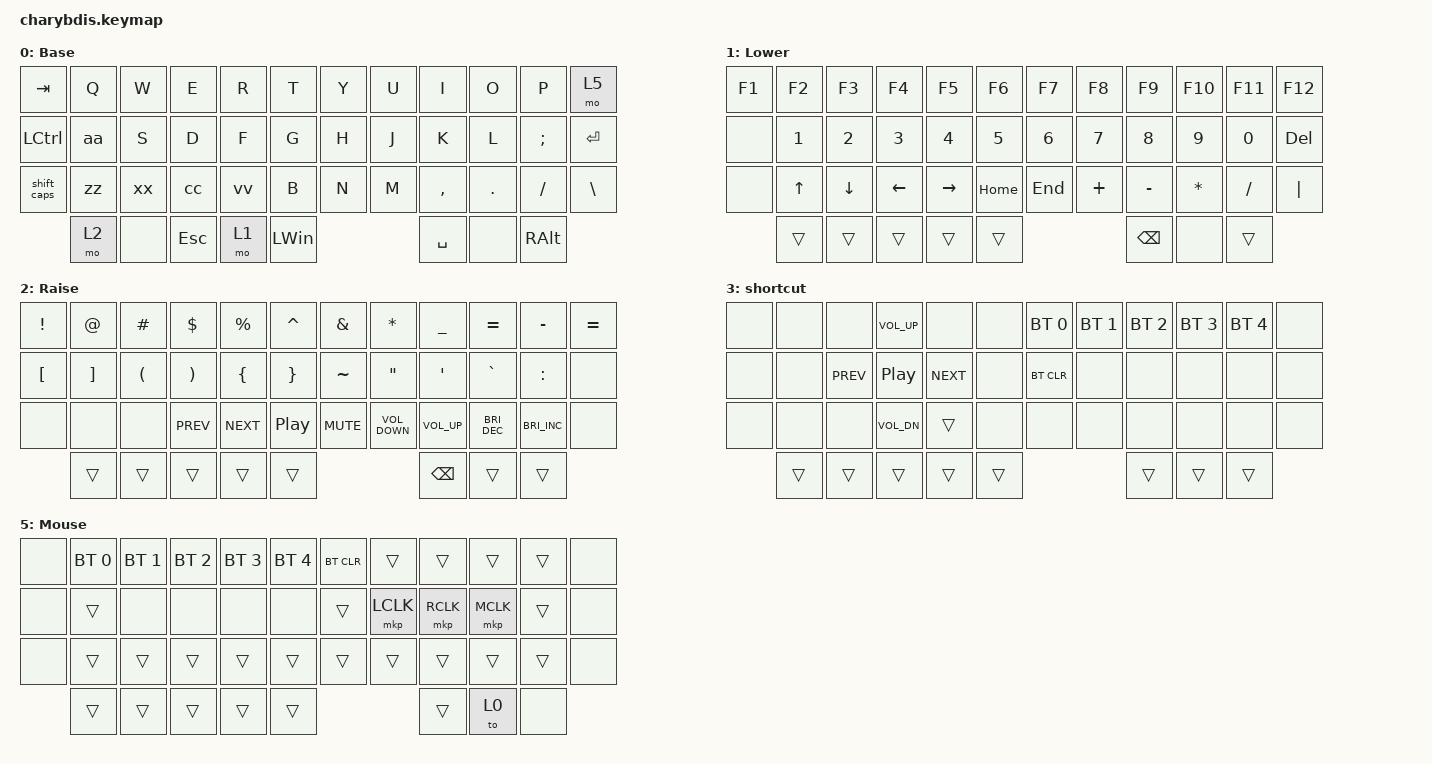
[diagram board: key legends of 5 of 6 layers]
#include <behaviors.dtsi>
#include <dt-bindings/zmk/bt.h>
#include <dt-bindings/zmk/keys.h>
#include <dt-bindings/zmk/mouse.h>

&lt {
    tapping-term-ms = <240>;
    flavor = "balanced";
    quick-tap-ms = <150>;
};

&mt {
    global-quick-tap;
    flavor = "tap-preferred";
    tapping-term-ms = <200>;
};

&sk {
    release-after-ms = <2000>;
    quick-release;
};

/ {
    combos {
        compatible = "zmk,combos";

        combo_esc {
            timeout-ms = <50>;
            key-positions = <0 1>;
            bindings = <&kp ESC>;
        };

        left_bkt {
            bindings = <&kp LEFT_BRACKET>;
            key-positions = <4 5>;
            timeout-ms = <50>;
        };

        right_bkt {
            bindings = <&kp RIGHT_BRACKET>;
            key-positions = <6 7>;
            timeout-ms = <50>;
        };

        left_par {
            bindings = <&kp LEFT_PARENTHESIS>;
            key-positions = <16 17>;
            timeout-ms = <50>;
        };

        right_par {
            bindings = <&kp RIGHT_PARENTHESIS>;
            key-positions = <18 19>;
            timeout-ms = <50>;
        };

        bac {
            bindings = <&kp BACKSLASH>;
            key-positions = <5 6>;
            timeout-ms = <50>;
        };

        pipe {
            bindings = <&kp PIPE>;
            key-positions = <17 18>;
            timeout-ms = <50>;
        };
    };

    behaviors {
        hm: homerow_mods {
            compatible = "zmk,behavior-hold-tap";
            label = "HOMEROW_MODS";
            bindings = <&kp>, <&kp>;

            #binding-cells = <2>;
            tapping-term-ms = <200>;
            quick-tap-ms = <180>;
            flavor = "tap-preferred";
        };

        ltq: ltq {
            compatible = "zmk,behavior-hold-tap";
            label = "LTQ";
            bindings = <&mo>, <&kp>;

            #binding-cells = <2>;
            tapping-term-ms = <200>;
            quick-tap-ms = <180>;
        };

        as: auto_shift {
            compatible = "zmk,behavior-hold-tap";
            label = "AUTO_SHIFT";
            bindings = <&kp>, <&kp>;

            #binding-cells = <2>;
            tapping-term-ms = <135>;
            quick-tap-ms = <0>;
        };

        shift_caps: shift_caps {
            compatible = "zmk,behavior-tap-dance";
            label = "shift_caps";
            #binding-cells = <0>;
            tapping-term-ms = <200>;
            bindings = <&kp LEFT_SHIFT>, <&caps_word>;
        };

        zz: zz {
            compatible = "zmk,behavior-tap-dance";
            label = "ZZ";
            #binding-cells = <0>;
            bindings = <&kp Z>, <&kp LC(Z)>;
        };

        xx: xx {
            compatible = "zmk,behavior-tap-dance";
            label = "XX";
            #binding-cells = <0>;
            bindings = <&kp X>, <&kp LC(X)>;
        };

        cc: cc {
            compatible = "zmk,behavior-tap-dance";
            label = "CC";
            #binding-cells = <0>;
            bindings = <&kp C>, <&kp LC(C)>;
        };

        vv: vv {
            compatible = "zmk,behavior-tap-dance";
            label = "VV";
            #binding-cells = <0>;
            bindings = <&kp V>, <&kp LC(V)>;
        };

        aa: aa {
            compatible = "zmk,behavior-tap-dance";
            label = "AA";
            #binding-cells = <0>;
            bindings = <&kp A>, <&kp LC(A)>;
        };
    };

    macros {
        macro1: new_macro {
            compatible = "zmk,behavior-macro";
            #binding-cells = <0>;
            bindings = <&kp RIGHT &kp ENTER>;
            label = "NEW_MACRO";
        };
    };

    keymap {
        compatible = "zmk,keymap";

        Base {
            label = "Base";
            bindings = <
&kp TAB      &kp Q  &kp W  &kp E       &kp R  &kp T         &kp Y  &kp U  &kp I      &kp O    &kp P          &mo 5
&kp LCTRL    &aa    &kp S  &kp D       &kp F  &kp G         &kp H  &kp J  &kp K      &kp L    &kp SEMI       &kp ENTER
&shift_caps  &zz    &xx    &cc         &vv    &kp B         &kp N  &kp M  &kp COMMA  &kp DOT  &kp FSLH       &kp BACKSLASH
             &mo 2  &none  &kp ESCAPE  &mo 1  &kp LEFT_WIN                &kp SPACE  &none    &kp RIGHT_ALT
            >;
        };

        Lower {
            label = "Lower";
            bindings = <
&kp F1  &kp F2        &kp F3        &kp F4        &kp F5        &kp F6        &kp F7        &kp F8        &kp F9         &kp F10       &kp F11       &kp F12
&none   &kp NUMBER_1  &kp NUMBER_2  &kp NUMBER_3  &kp NUMBER_4  &kp NUMBER_5  &kp NUMBER_6  &kp NUMBER_7  &kp NUMBER_8   &kp NUMBER_9  &kp NUMBER_0  &kp DELETE
&none   &kp UP_ARROW  &kp DOWN      &kp LEFT      &kp RIGHT     &kp HOME      &kp END       &kp PLUS      &kp MINUS      &kp ASTERISK  &kp SLASH     &kp PIPE
        &trans        &trans        &trans        &trans        &trans                                    &kp BACKSPACE  &none         &trans
            >;
        };

        Raise {
            label = "Raise";
            bindings = <
&kp EXCLAMATION   &kp AT_SIGN        &kp HASH              &kp DOLLAR             &kp PERCENT     &kp CARET        &kp AMPERSAND  &kp ASTERISK       &kp UNDERSCORE   &kp EQUAL      &kp MINUS      &kp EQUAL
&kp LEFT_BRACKET  &kp RIGHT_BRACKET  &kp LEFT_PARENTHESIS  &kp RIGHT_PARENTHESIS  &kp LEFT_BRACE  &kp RIGHT_BRACE  &kp TILDE      &kp DOUBLE_QUOTES  &kp SQT          &kp GRAVE      &kp COLON      &none
&none             &none              &none                 &kp C_PREV             &kp C_NEXT      &kp C_PP         &kp C_MUTE     &kp C_VOLUME_DOWN  &kp C_VOLUME_UP  &kp C_BRI_DEC  &kp C_BRI_INC  &none
                  &trans             &trans                &trans                 &trans          &trans                                             &kp BACKSPACE    &trans         &trans
            >;
        };

        Shortcut {
            label = "shortcut";
            bindings = <
&none  &none   &none       &kp C_VOL_UP  &none       &none   &bt BT_SEL 0  &bt BT_SEL 1  &bt BT_SEL 2  &bt BT_SEL 3  &bt BT_SEL 4  &none
&none  &none   &kp C_PREV  &kp C_PP      &kp C_NEXT  &none   &bt BT_CLR    &none         &none         &none         &none         &none
&none  &none   &none       &kp C_VOL_DN  &trans      &none   &none         &none         &none         &none         &none         &none
       &trans  &trans      &trans        &trans      &trans                              &trans        &trans        &trans
            >;
        };

        Game {
            label = "Game";
            bindings = <
&none   &trans  &trans  &trans  &none   &trans  &trans  &trans  &trans  &trans  &none  &none
&trans  &trans  &trans  &trans  &trans  &none   &none   &none   &none   &none   &none  &none
&none   &none   &none   &none   &none   &none   &none   &none   &none   &none   &none  &none
        &none   &none   &none   &none   &none                   &none   &none
            >;
        };

        Mouse {
            bindings = <
&none  &bt BT_SEL 0  &bt BT_SEL 1  &bt BT_SEL 2  &bt BT_SEL 3  &bt BT_SEL 4  &bt BT_CLR  &trans     &trans     &trans     &trans  &none
&none  &trans        &none         &none         &none         &none         &trans      &mkp LCLK  &mkp RCLK  &mkp MCLK  &trans  &none
&none  &trans        &trans        &trans        &trans        &trans        &trans      &trans     &trans     &trans     &trans  &none
       &trans        &trans        &trans        &trans        &trans                               &trans     &to 0      &none
            >;
        };
    };
};
